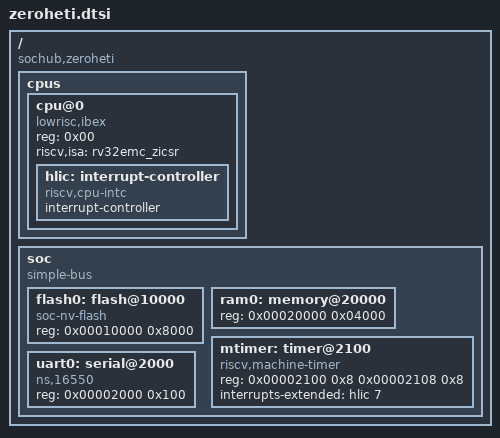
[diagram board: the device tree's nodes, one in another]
/*
 * Copyright (c) 2023 by Rivos Inc.
 *
 * SPDX-License-Identifier: Apache-2.0
 */

/ {
	#address-cells = <0x01>;
	#size-cells = <0x01>;
	compatible = "sochub,zeroheti";

	cpus {
		#address-cells = <0x01>;
		#size-cells = <0x00>;

		cpu@0 {
			device_type = "cpu";
			reg = <0x00>;
			status = "okay";
			compatible = "lowrisc,ibex", "riscv";
			riscv,isa = "rv32emc_zicsr";

			hlic: interrupt-controller {
				#interrupt-cells = <0x01>;
				interrupt-controller;
				compatible = "riscv,cpu-intc";
			};
		};
	};

	soc {
		#address-cells = <0x01>;
		#size-cells = <0x01>;
		compatible = "simple-bus";
		ranges;

		flash0: flash@10000 {
			reg = <0x00010000 0x8000>;
			compatible = "soc-nv-flash";
		};

		ram0: memory@20000 {
			device_type = "memory";
			reg = <0x00020000 0x04000>;
		};

		mtimer: timer@2100 {
			compatible = "riscv,machine-timer";
			reg = <0x00002100 0x8 0x00002108 0x8>;
			reg-names = "mtime", "mtimecmp";
			interrupts-extended = <&hlic 7>;
		};

		uart0: serial@2000 {
			reg = <0x00002000 0x100>;
			compatible = "ns,16550";
		};
	};
};

